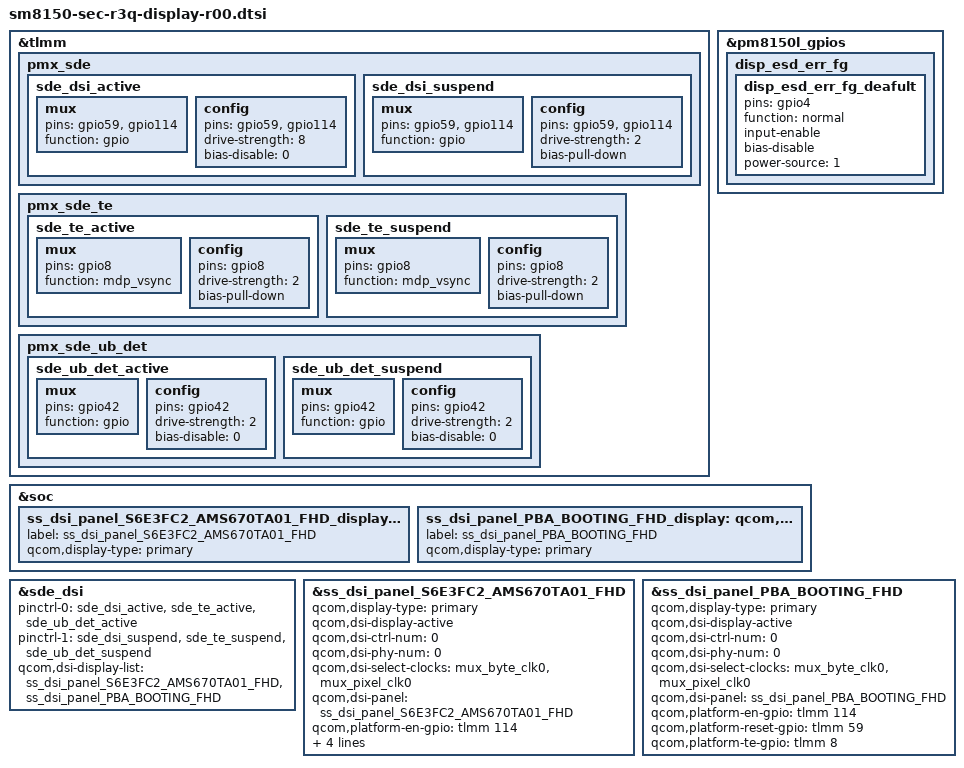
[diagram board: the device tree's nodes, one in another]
/* Copyright (c) 2016-2019, The Linux Foundation. All rights reserved.
 *
 * This program is free software; you can redistribute it and/or modify
 * it under the terms of the GNU General Public License version 2 and
 * only version 2 as published by the Free Software Foundation.
 *
 * This program is distributed in the hope that it will be useful,
 * but WITHOUT ANY WARRANTY; without even the implied warranty of
 * MERCHANTABILITY or FITNESS FOR A PARTICULAR PURPOSE.  See the
 * GNU General Public License for more details.
 */

#include "../../../../../drivers/gpu/drm/msm/samsung/S6E3FC2_AMS670TA01/dsi_panel_S6E3FC2_AMS670TA01_fhd_octa_cmd.dtsi"
#include "../../../../../drivers/gpu/drm/msm/samsung/PBA_BOOTING/dsi_panel_PBA_BOOTING_fhd_video.dtsi"

&tlmm {
	pmx_sde: pmx_sde {
		sde_dsi_active: sde_dsi_active {
			mux {
				pins = "gpio59","gpio114";
				function = "gpio";
			};

			config {
				pins = "gpio59","gpio114";
				drive-strength = <8>;   /* 8 mA */
				bias-disable = <0>;   /* no pull */
			};
		};
		sde_dsi_suspend: sde_dsi_suspend {
			mux {
				pins = "gpio59","gpio114";
				function = "gpio";
			};

			config {
				pins = "gpio59","gpio114";
				drive-strength = <2>;   /* 2 mA */
				bias-pull-down;         /* PULL DOWN */
			};
		};
	};

	pmx_sde_te {
		sde_te_active: sde_te_active {
			mux {
				pins = "gpio8";
				function = "mdp_vsync";
			};

			config {
				pins = "gpio8";
				drive-strength = <2>;   /* 2 mA */
				bias-pull-down;         /* PULL DOWN */
			};
		};

		sde_te_suspend: sde_te_suspend {
			mux {
				pins = "gpio8";
				function = "mdp_vsync";
			};

			config {
				pins = "gpio8";
				drive-strength = <2>;   /* 2 mA */
				bias-pull-down;         /* PULL DOWN */
			};
		};
	};

	pmx_sde_ub_det {
		sde_ub_det_active: sde_ub_det_active {	/* UB_CON_DET */
			mux {
				pins = "gpio42";
				function = "gpio";
			};

			config {
				pins = "gpio42";
				drive-strength = <2>;   /* 2 mA */
				bias-disable = <0>;   /* no pull */
			};
		};

		sde_ub_det_suspend: sde_ub_det_suspend {
			mux {
				pins = "gpio42";
				function = "gpio";
			};

			config {
				pins = "gpio42";
				drive-strength = <2>;   /* 2 mA */
				bias-disable = <0>;   /* no pull */
			};
		};
	};
};

&pm8150l_gpios {
	disp_esd_err_fg {
		disp_esd_err_fg_deafult: disp_esd_err_fg_deafult { // FG_ERR
			pins = "gpio4";
			function = "normal";
			input-enable;
			bias-disable;
			power-source = <1>;
		};
	};
};

&soc {
	/* R3_Rev_00 panel */
	ss_dsi_panel_S6E3FC2_AMS670TA01_FHD_display: qcom,dsi-display@0 {
		label = "ss_dsi_panel_S6E3FC2_AMS670TA01_FHD";
		qcom,display-type = "primary";
	};

	/* PBA */
	ss_dsi_panel_PBA_BOOTING_FHD_display: qcom,dsi-display@1 {
		label = "ss_dsi_panel_PBA_BOOTING_FHD";
		qcom,display-type = "primary";
	};
};

&sde_dsi {
	pinctrl-names = "panel_active", "panel_suspend";
	pinctrl-0 = <&sde_dsi_active &sde_te_active &sde_ub_det_active>;
	pinctrl-1 = <&sde_dsi_suspend &sde_te_suspend &sde_ub_det_suspend>;

	qcom,dsi-display-list =
		<&ss_dsi_panel_S6E3FC2_AMS670TA01_FHD
		&ss_dsi_panel_PBA_BOOTING_FHD>;
};

&ss_dsi_panel_S6E3FC2_AMS670TA01_FHD {
	qcom,display-type = "primary";
	qcom,dsi-display-active;

	qcom,dsi-ctrl-num = <0>;
	qcom,dsi-phy-num = <0>;
	qcom,dsi-select-clocks = "mux_byte_clk0", "mux_pixel_clk0";

	qcom,dsi-panel = <&ss_dsi_panel_S6E3FC2_AMS670TA01_FHD>;

	qcom,platform-en-gpio = <&tlmm 114 0>;
	qcom,platform-reset-gpio = <&tlmm 59 0>;
	qcom,platform-te-gpio = <&tlmm 8 0>;
	samsung,ub-con-det = <&tlmm 42 0>; // UB_CON_DET
	samsung,support-optical-fingerprint;
};

&ss_dsi_panel_PBA_BOOTING_FHD {
	qcom,display-type = "primary";
	qcom,dsi-display-active;

	qcom,dsi-ctrl-num = <0>;
	qcom,dsi-phy-num = <0>;
	qcom,dsi-select-clocks = "mux_byte_clk0", "mux_pixel_clk0";

	qcom,dsi-panel = <&ss_dsi_panel_PBA_BOOTING_FHD>;

	qcom,platform-en-gpio = <&tlmm 114 0>;
	qcom,platform-reset-gpio = <&tlmm 59 0>;
	qcom,platform-te-gpio = <&tlmm 8 0>;
};
